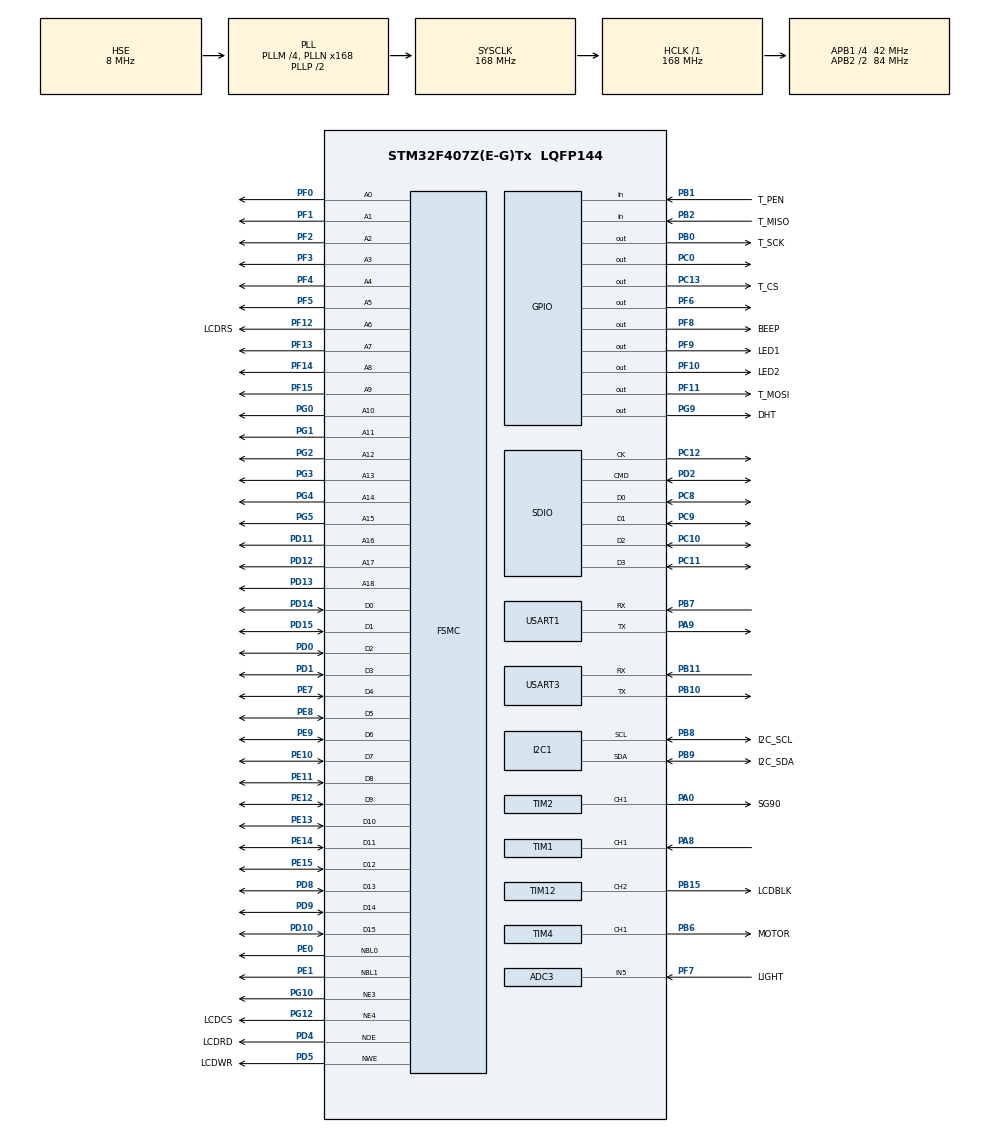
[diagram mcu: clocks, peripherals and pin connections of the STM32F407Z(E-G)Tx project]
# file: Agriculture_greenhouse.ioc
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ADC3.Channel-0\#ChannelRegularConversion=ADC_CHANNEL_5
ADC3.NbrOfConversionFlag=1
ADC3.Rank-0\#ChannelRegularConversion=1
ADC3.SamplingTime-0\#ChannelRegularConversion=ADC_SAMPLETIME_3CYCLES
Dma.Request0=SDIO_RX
Dma.Request1=SDIO_TX
Dma.SDIO_RX.0.Direction=DMA_PERIPH_TO_MEMORY
Dma.SDIO_RX.0.FIFOMode=DMA_FIFOMODE_ENABLE
Dma.SDIO_RX.0.FIFOThreshold=DMA_FIFO_THRESHOLD_FULL
Dma.SDIO_RX.0.Instance=DMA2_Stream3
Dma.SDIO_RX.0.MemBurst=DMA_MBURST_INC4
Dma.SDIO_RX.0.MemDataAlignment=DMA_MDATAALIGN_WORD
Dma.SDIO_RX.0.MemInc=DMA_MINC_ENABLE
Dma.SDIO_RX.0.Mode=DMA_PFCTRL
Dma.SDIO_RX.0.PeriphBurst=DMA_PBURST_INC4
Dma.SDIO_RX.0.PeriphDataAlignment=DMA_PDATAALIGN_WORD
Dma.SDIO_RX.0.PeriphInc=DMA_PINC_DISABLE
Dma.SDIO_RX.0.Priority=DMA_PRIORITY_HIGH
Dma.SDIO_TX.1.Direction=DMA_MEMORY_TO_PERIPH
Dma.SDIO_TX.1.FIFOMode=DMA_FIFOMODE_ENABLE
Dma.SDIO_TX.1.FIFOThreshold=DMA_FIFO_THRESHOLD_FULL
Dma.SDIO_TX.1.Instance=DMA2_Stream6
Dma.SDIO_TX.1.MemBurst=DMA_MBURST_INC4
Dma.SDIO_TX.1.MemDataAlignment=DMA_MDATAALIGN_WORD
Dma.SDIO_TX.1.MemInc=DMA_MINC_ENABLE
Dma.SDIO_TX.1.Mode=DMA_PFCTRL
Dma.SDIO_TX.1.PeriphBurst=DMA_PBURST_INC4
Dma.SDIO_TX.1.PeriphDataAlignment=DMA_PDATAALIGN_WORD
Dma.SDIO_TX.1.PeriphInc=DMA_PINC_DISABLE
Dma.SDIO_TX.1.Priority=DMA_PRIORITY_HIGH
FATFS._CODE_PAGE=936
FREERTOS.INCLUDE_vTaskDelayUntil=1
FREERTOS.MEMORY_ALLOCATION=0
FREERTOS.Tasks01=defaultTask,0,128,StartDefaultTask,Default,NULL,Dynamic,NULL,NULL
FREERTOS.configTOTAL_HEAP_SIZE=40960
FSMC.AddressSetupTime3=0
FSMC.BusTurnAroundDuration3=0
FSMC.DataSetupTime3=8
FSMC.ExtendedAddressSetupTime1=2
FSMC.ExtendedMode1=FSMC_EXTENDED_MODE_ENABLE
FSMC.WriteOperation3=FSMC_WRITE_OPERATION_ENABLE
Mcu.Family=STM32F4
Mcu.Name=STM32F407Z(E-G)Tx
Mcu.Package=LQFP144
NVIC.DMA2_Stream3_IRQn=true\:5\:0\:false\:false\:true\:true\:false\:true\:true
NVIC.DMA2_Stream6_IRQn=true\:5\:0\:false\:false\:true\:true\:false\:true\:true
NVIC.PriorityGroup=NVIC_PRIORITYGROUP_4
NVIC.SDIO_IRQn=true\:5\:0\:false\:false\:true\:true\:true\:true\:true
NVIC.TIM1_CC_IRQn=true\:5\:0\:false\:false\:true\:true\:true\:true\:true
NVIC.TIM1_UP_TIM10_IRQn=true\:5\:0\:false\:false\:true\:true\:true\:true\:true
NVIC.USART3_IRQn=true\:5\:0\:false\:false\:true\:true\:true\:true\:true
PA0-WKUP.GPIO_Label=SG90
PA0-WKUP.GPIO_PuPd=GPIO_PULLUP
PA0-WKUP.GPIO_Speed=GPIO_SPEED_FREQ_HIGH
PA0-WKUP.Signal=S_TIM2_CH1_ETR
PA13.Mode=Serial_Wire
PA13.Signal=SYS_JTMS-SWDIO
PA14.Mode=Serial_Wire
PA14.Signal=SYS_JTCK-SWCLK
PA8.GPIO_PuPd=GPIO_PULLUP
PA8.GPIO_Speed=GPIO_SPEED_FREQ_HIGH
PA8.Signal=S_TIM1_CH1
PA9.Mode=Asynchronous
PA9.Signal=USART1_TX
PB0.GPIO_Label=T_SCK
PB0.GPIO_PuPd=GPIO_PULLUP
PB0.Signal=GPIO_Output
PB1.GPIO_Label=T_PEN
PB1.GPIO_PuPd=GPIO_PULLUP
PB1.Signal=GPIO_Input
PB10.Mode=Asynchronous
PB10.Signal=USART3_TX
PB11.Mode=Asynchronous
PB11.Signal=USART3_RX
PB15.GPIO_Label=LCDBLK
PB15.GPIO_Speed=GPIO_SPEED_FREQ_HIGH
PB15.Signal=S_TIM12_CH2
PB2.GPIO_Label=T_MISO
PB2.GPIO_PuPd=GPIO_PULLUP
PB2.Signal=GPIO_Input
PB6.GPIO_Label=MOTOR
PB6.Signal=S_TIM4_CH1
PB7.Mode=Asynchronous
PB7.Signal=USART1_RX
PB8.GPIO_Label=I2C_SCL
PB8.GPIO_Pu=GPIO_PULLUP
PB8.GPIO_Speed=GPIO_SPEED_FREQ_VERY_HIGH
PB8.Mode=I2C
PB8.Signal=I2C1_SCL
PB9.GPIO_Label=I2C_SDA
PB9.GPIO_Pu=GPIO_PULLUP
PB9.Mode=I2C
PB9.Signal=I2C1_SDA
PC0.PinState=GPIO_PIN_SET
PC0.Signal=GPIO_Output
PC10.GPIO_PuPd=GPIO_PULLUP
PC10.Mode=SD_4_bits_Wide_bus
PC10.Signal=SDIO_D2
PC11.GPIO_PuPd=GPIO_PULLUP
PC11.Mode=SD_4_bits_Wide_bus
PC11.Signal=SDIO_D3
PC12.GPIO_PuPd=GPIO_PULLUP
PC12.Mode=SD_4_bits_Wide_bus
PC12.Signal=SDIO_CK
PC13-ANTI_TAMP.GPIO_Label=T_CS
PC13-ANTI_TAMP.GPIO_PuPd=GPIO_PULLUP
PC13-ANTI_TAMP.Signal=GPIO_Output
PC14-OSC32_IN.Mode=LSE-External-Oscillator
PC14-OSC32_IN.Signal=RCC_OSC32_IN
PC15-OSC32_OUT.Mode=LSE-External-Oscillator
PC15-OSC32_OUT.Signal=RCC_OSC32_OUT
PC8.GPIO_PuPd=GPIO_PULLUP
PC8.Mode=SD_4_bits_Wide_bus
PC8.Signal=SDIO_D0
PC9.GPIO_PuPd=GPIO_PULLUP
PC9.Mode=SD_4_bits_Wide_bus
PC9.Signal=SDIO_D1
PD0.GPIO_PuPd=GPIO_PULLUP
PD0.Signal=FSMC_D2_DA2
PD1.GPIO_PuPd=GPIO_PULLUP
PD1.Signal=FSMC_D3_DA3
PD10.GPIO_PuPd=GPIO_PULLUP
PD10.Signal=FSMC_D15_DA15
PD11.Signal=FSMC_A16_CLE
PD12.Signal=FSMC_A17_ALE
PD13.Signal=FSMC_A18
PD14.GPIO_PuPd=GPIO_PULLUP
PD14.Signal=FSMC_D0_DA0
PD15.GPIO_PuPd=GPIO_PULLUP
PD15.Signal=FSMC_D1_DA1
PD2.GPIO_PuPd=GPIO_PULLUP
PD2.Mode=SD_4_bits_Wide_bus
PD2.Signal=SDIO_CMD
PD4.GPIO_Label=LCDRD
PD4.GPIO_PuPd=GPIO_PULLUP
PD4.Signal=FSMC_NOE
PD5.GPIO_Label=LCDWR
PD5.GPIO_PuPd=GPIO_PULLUP
PD5.Signal=FSMC_NWE
PD8.GPIO_PuPd=GPIO_PULLUP
PD8.Signal=FSMC_D13_DA13
PD9.GPIO_PuPd=GPIO_PULLUP
PD9.Signal=FSMC_D14_DA14
PE0.Signal=FSMC_NBL0
PE1.Signal=FSMC_NBL1
PE10.GPIO_PuPd=GPIO_PULLUP
PE10.Signal=FSMC_D7_DA7
PE11.GPIO_PuPd=GPIO_PULLUP
PE11.Signal=FSMC_D8_DA8
PE12.GPIO_PuPd=GPIO_PULLUP
PE12.Signal=FSMC_D9_DA9
PE13.GPIO_PuPd=GPIO_PULLUP
PE13.Signal=FSMC_D10_DA10
PE14.GPIO_PuPd=GPIO_PULLUP
PE14.Signal=FSMC_D11_DA11
PE15.GPIO_PuPd=GPIO_PULLUP
PE15.Signal=FSMC_D12_DA12
PE7.GPIO_PuPd=GPIO_PULLUP
PE7.Signal=FSMC_D4_DA4
PE8.GPIO_PuPd=GPIO_PULLUP
PE8.Signal=FSMC_D5_DA5
PE9.GPIO_PuPd=GPIO_PULLUP
PE9.Signal=FSMC_D6_DA6
PF0.Signal=FSMC_A0
PF1.Signal=FSMC_A1
PF10.GPIO_Label=LED2
PF10.GPIO_PuPd=GPIO_NOPULL
PF10.GPIO_Speed=GPIO_SPEED_FREQ_LOW
PF10.Signal=GPIO_Output
PF11.GPIO_Label=T_MOSI
PF11.GPIO_PuPd=GPIO_PULLUP
PF11.GPIO_Speed=GPIO_SPEED_FREQ_HIGH
PF11.Signal=GPIO_Output
PF12.GPIO_Label=LCDRS
PF12.GPIO_PuPd=GPIO_PULLUP
PF12.Signal=FSMC_A6
PF13.Signal=FSMC_A7
PF14.Signal=FSMC_A8
PF15.Signal=FSMC_A9
PF2.Signal=FSMC_A2
PF3.Signal=FSMC_A3
PF4.Signal=FSMC_A4
PF5.Signal=FSMC_A5
PF6.PinState=GPIO_PIN_SET
PF6.Signal=GPIO_Output
PF7.GPIO_Label=LIGHT
PF7.Mode=IN5
PF7.Signal=ADC3_IN5
PF8.GPIO_Label=BEEP
PF8.GPIO_PuPd=GPIO_NOPULL
PF8.GPIO_Speed=GPIO_SPEED_FREQ_LOW
PF8.Signal=GPIO_Output
PF9.GPIO_Label=LED1
PF9.GPIO_PuPd=GPIO_NOPULL
PF9.GPIO_Speed=GPIO_SPEED_FREQ_LOW
PF9.Signal=GPIO_Output
PG0.Signal=FSMC_A10
PG1.Signal=FSMC_A11
PG10.Mode=NorPsramChipSelect3_3
PG10.Signal=FSMC_NE3
PG12.GPIO_Label=LCDCS
PG12.GPIO_PuPd=GPIO_PULLUP
PG12.Mode=NorPsramChipSelect4_1
PG12.Signal=FSMC_NE4
PG2.Signal=FSMC_A12
PG3.Signal=FSMC_A13
PG4.Signal=FSMC_A14
PG5.Signal=FSMC_A15
PG9.GPIO_Label=DHT
PG9.GPIO_ModeDefaultOutputPP=GPIO_MODE_OUTPUT_PP
PG9.GPIO_PuPd=GPIO_PULLUP
PG9.GPIO_Speed=GPIO_SPEED_FREQ_HIGH
PG9.PinState=GPIO_PIN_RESET
PG9.Signal=GPIO_Output
PH0-OSC_IN.Mode=HSE-External-Oscillator
PH0-OSC_IN.Signal=RCC_OSC_IN
PH1-OSC_OUT.Mode=HSE-External-Oscillator
PH1-OSC_OUT.Signal=RCC_OSC_OUT
ProjectManager.HeapSize=0x200
ProjectManager.StackSize=0x400
ProjectManager.TargetToolchain=MDK-ARM V5
RCC.48MHZClocksFreq_Value=48000000
RCC.AHBFreq_Value=168000000
RCC.APB1CLKDivider=RCC_HCLK_DIV4
RCC.APB1Freq_Value=42000000
RCC.APB1TimFreq_Value=84000000
RCC.APB2CLKDivider=RCC_HCLK_DIV2
RCC.APB2Freq_Value=84000000
RCC.APB2TimFreq_Value=168000000
RCC.CortexFreq_Value=168000000
RCC.HCLKFreq_Value=168000000
RCC.HSE_VALUE=8000000
RCC.HSI_VALUE=16000000
RCC.PLLM=4
RCC.PLLN=168
RCC.PLLQ=7
RCC.PLLSourceVirtual=RCC_PLLSOURCE_HSE
RCC.RCC_RTC_Clock_Source=RCC_RTCCLKSOURCE_LSE
RCC.RCC_RTC_Clock_SourceVirtual=RCC_RTCCLKSOURCE_LSE
RCC.SYSCLKFreq_VALUE=168000000
RCC.SYSCLKSource=RCC_SYSCLKSOURCE_PLLCLK
RCC.VCOOutputFreq_Value=336000000
SDIO.ClockDiv=4
SH.FSMC_A0.0=FSMC_A0,19b-a3
SH.FSMC_A1.0=FSMC_A1,19b-a3
SH.FSMC_A10.0=FSMC_A10,19b-a3
SH.FSMC_A11.0=FSMC_A11,19b-a3
SH.FSMC_A12.0=FSMC_A12,19b-a3
SH.FSMC_A13.0=FSMC_A13,19b-a3
SH.FSMC_A14.0=FSMC_A14,19b-a3
SH.FSMC_A15.0=FSMC_A15,19b-a3
SH.FSMC_A16_CLE.0=FSMC_A16,19b-a3
SH.FSMC_A17_ALE.0=FSMC_A17,19b-a3
SH.FSMC_A18.0=FSMC_A18,19b-a3
SH.FSMC_A2.0=FSMC_A2,19b-a3
SH.FSMC_A3.0=FSMC_A3,19b-a3
SH.FSMC_A4.0=FSMC_A4,19b-a3
SH.FSMC_A5.0=FSMC_A5,19b-a3
SH.FSMC_A6.0=FSMC_A6,A6_1
SH.FSMC_A6.1=FSMC_A6,19b-a3
SH.FSMC_A7.0=FSMC_A7,19b-a3
SH.FSMC_A8.0=FSMC_A8,19b-a3
SH.FSMC_A9.0=FSMC_A9,19b-a3
SH.FSMC_D0_DA0.0=FSMC_D0,16b-d1
SH.FSMC_D0_DA0.1=FSMC_D0,16b-d3
SH.FSMC_D10_DA10.0=FSMC_D10,16b-d1
SH.FSMC_D10_DA10.1=FSMC_D10,16b-d3
SH.FSMC_D11_DA11.0=FSMC_D11,16b-d1
SH.FSMC_D11_DA11.1=FSMC_D11,16b-d3
SH.FSMC_D12_DA12.0=FSMC_D12,16b-d1
SH.FSMC_D12_DA12.1=FSMC_D12,16b-d3
SH.FSMC_D13_DA13.0=FSMC_D13,16b-d1
SH.FSMC_D13_DA13.1=FSMC_D13,16b-d3
SH.FSMC_D14_DA14.0=FSMC_D14,16b-d1
SH.FSMC_D14_DA14.1=FSMC_D14,16b-d3
SH.FSMC_D15_DA15.0=FSMC_D15,16b-d1
SH.FSMC_D15_DA15.1=FSMC_D15,16b-d3
SH.FSMC_D1_DA1.0=FSMC_D1,16b-d1
SH.FSMC_D1_DA1.1=FSMC_D1,16b-d3
SH.FSMC_D2_DA2.0=FSMC_D2,16b-d1
SH.FSMC_D2_DA2.1=FSMC_D2,16b-d3
SH.FSMC_D3_DA3.0=FSMC_D3,16b-d1
SH.FSMC_D3_DA3.1=FSMC_D3,16b-d3
SH.FSMC_D4_DA4.0=FSMC_D4,16b-d1
SH.FSMC_D4_DA4.1=FSMC_D4,16b-d3
SH.FSMC_D5_DA5.0=FSMC_D5,16b-d1
SH.FSMC_D5_DA5.1=FSMC_D5,16b-d3
SH.FSMC_D6_DA6.0=FSMC_D6,16b-d1
SH.FSMC_D6_DA6.1=FSMC_D6,16b-d3
SH.FSMC_D7_DA7.0=FSMC_D7,16b-d1
SH.FSMC_D7_DA7.1=FSMC_D7,16b-d3
SH.FSMC_D8_DA8.0=FSMC_D8,16b-d1
SH.FSMC_D8_DA8.1=FSMC_D8,16b-d3
SH.FSMC_D9_DA9.0=FSMC_D9,16b-d1
SH.FSMC_D9_DA9.1=FSMC_D9,16b-d3
SH.FSMC_NBL0.0=FSMC_NBL0,2ByteEnable3
SH.FSMC_NBL1.0=FSMC_NBL1,2ByteEnable3
SH.FSMC_NOE.0=FSMC_NOE,Lcd1
SH.FSMC_NOE.1=FSMC_NOE,Sram3
SH.FSMC_NWE.0=FSMC_NWE,Lcd1
SH.FSMC_NWE.1=FSMC_NWE,Sram3
SH.S_TIM12_CH2.0=TIM12_CH2,PWM Generation2 CH2
SH.S_TIM1_CH1.0=TIM1_CH1,Input_Capture1_from_TI1
SH.S_TIM2_CH1_ETR.0=TIM2_CH1,PWM Generation1 CH1
SH.S_TIM4_CH1.0=TIM4_CH1,PWM Generation1 CH1
TIM1.AutoReloadPreload=TIM_AUTORELOAD_PRELOAD_ENABLE
TIM1.Channel-Input_Capture1_from_TI1=TIM_CHANNEL_1
TIM1.ICFilter_CH1=3
TIM1.Period=10000
TIM1.Prescaler=167
TIM12.Channel-PWM\ Generation2\ CH2=TIM_CHANNEL_2
TIM12.Period=255
TIM12.Prescaler=83
TIM2.Channel-PWM\ Generation1\ CH1=TIM_CHANNEL_1
TIM2.Period=1999
TIM2.Prescaler=839
TIM2.Pulse-PWM\ Generation1\ CH1=150
TIM3.Prescaler=83
TIM4.Channel-PWM\ Generation1\ CH1=TIM_CHANNEL_1
TIM4.Period=99
TIM4.Prescaler=83
USART1.VirtualMode=VM_ASYNC
USART3.VirtualMode=VM_ASYNC
VP_FATFS_VS_SDIO.Mode=SDIO
VP_FREERTOS_VS_CMSIS_V1.Mode=CMSIS_V1
VP_RTC_VS_RTC_Activate.Mode=RTC_Enabled
VP_TIM1_VS_ClockSourceINT.Mode=Internal
VP_TIM2_VS_ClockSourceINT.Mode=Internal
VP_TIM3_VS_ClockSourceINT.Mode=Internal
VP_TIM4_VS_ClockSourceINT.Mode=Internal
board=custom

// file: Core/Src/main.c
/* USER CODE BEGIN Header */
/**
  ******************************************************************************
  * @file           : main.c
  * @brief          : Main program body
  ******************************************************************************
  * @attention
  *
  * Copyright (c) 2026 STMicroelectronics.
  * All rights reserved.
  *
  * This software is licensed under terms that can be found in the LICENSE file
  * in the root directory of this software component.
  * If no LICENSE file comes with this software, it is provided AS-IS.
  *
  ******************************************************************************
  */
/* USER CODE END Header */
#include "main.h"
#include "cmsis_os.h"
#include "adc.h"
#include "dma.h"
#include "fatfs.h"
#include "i2c.h"
#include "rtc.h"
#include "sdio.h"
#include "tim.h"
#include "usart.h"
#include "gpio.h"
#include "fsmc.h"

/* USER CODE BEGIN Includes */
#include "lcd.h"
#include "lcd_draw.h"
#include "touch.h"
#include "esp8266.h"
#include "remote.h"
#include "sensor_data.h"
#include <string.h>
#include "cloud_sync.h"
#include "esp8266.h"
/* USER CODE END Includes */

/* USER CODE BEGIN PD */
#define WIFI_SSID         "hahaha"
#define WIFI_PASSWORD     "dong00407"
#define SERVER_IP         "10.17.102.190"
#define SERVER_PORT       5000
/* USER CODE END PD */

void SystemClock_Config(void);
void MX_FREERTOS_Init(void);

/* USER CODE BEGIN 0 */
// printf重定义
int fputc(int ch, FILE *f)
{
	HAL_UART_Transmit(&huart1, (uint8_t *)&ch, 1, 10);//0xffff
	return ch;
}
// int fputc(int ch, FILE *f)
// {
//     // 使用中断发送，不阻塞
//     HAL_UART_Transmit_IT(&huart1, (uint8_t *)&ch, 1);
//     // 等待发送完成（带超时）
//     uint32_t timeout = 1000;
//     while (huart1.gState != HAL_UART_STATE_READY && --timeout);
//     return ch;
// }

/*微秒延时函数*/
void delay_us(uint32_t us)
{
  __HAL_TIM_SET_COUNTER(&htim3, 0);  // 重置计数器
  HAL_TIM_Base_Start(&htim3);  // 启动定时器
  while (__HAL_TIM_GET_COUNTER(&htim3) < us);  // 等待计数完成
  HAL_TIM_Base_Stop(&htim3);  // 停止定时器
}
/* USER CODE END 0 */

int main(void)
{

  /* MCU Configuration--------------------------------------------------------*/

  /* Reset of all peripherals, Initializes the Flash interface and the Systick. */
  HAL_Init();

  /* Configure the system clock */
  SystemClock_Config();

  /* Initialize all configured peripherals */
  MX_GPIO_Init();
  MX_DMA_Init();
  MX_USART1_UART_Init();
  MX_TIM2_Init();
  MX_TIM3_Init();
  MX_TIM12_Init();
  MX_ADC3_Init();
  MX_FSMC_Init();
  MX_SDIO_SD_Init();
  MX_FATFS_Init();
  MX_RTC_Init();
  MX_USART3_UART_Init();
  MX_TIM1_Init();
  MX_I2C1_Init();
  MX_TIM4_Init();
  /* USER CODE BEGIN 2 */
  // 启动 PWM
  HAL_TIM_PWM_Start(&htim12, TIM_CHANNEL_2);
  __HAL_TIM_SetCompare(&htim12, TIM_CHANNEL_2, 125); // 设置亮度 0-255

  HAL_TIM_PWM_Start(&htim4, TIM_CHANNEL_1); // 启动定时器4的PWM输出，通道1用于控制直流电机
  HAL_TIM_PWM_Start(&htim2, TIM_CHANNEL_1); // 启动定时器2的PWM输出，通道1用于控制SG90舵机
  __HAL_TIM_SetCompare(&htim2, TIM_CHANNEL_1, 150); // 初始化舵机角度为90度

  HAL_GPIO_WritePin(LED1_GPIO_Port,LED1_Pin,GPIO_PIN_SET);
  HAL_GPIO_WritePin(LED2_GPIO_Port,LED2_Pin,GPIO_PIN_SET);

  // LCD初始化
  lcd_Init();

  // 触摸初始化
  tp_dev.init();

  // 光照传感器初始化
  BH1750_Init();

  ESP8266_SendCmd("AT+RST\r\n", "OK", 3000);
  HAL_Delay(1500);
  ESP8266_Init(WIFI_SSID, WIFI_PASSWORD);

  // 启动服务器
  ESP8266_SendCmd("AT+CIPSERVER=1,80\r\n", "OK", 2000);
  printf("服务器已启动, IP: 10.17.102.247\r\n");

  // int count = 0;
  //   while (1)
  //   {
  //       // ===== 1. 检查是否有队友指令 =====
  //   if (USART3_RX_STA & 0x8000)
  //   {
  //     char *p = strstr(USART3_RX_BUF, "+IPD,");
  //       if (p && strstr(p, "GET /control"))
  //   {
  //       printf("\r\n===== 收到指令 =====\r\n");

  //       // 1. 解析 link_id
  //       int link_id = 0;
  //       sscanf(p, "+IPD,%d,", &link_id);

  //       // 2. 构造响应体 (Body)
  //       char body[] = "{\"status\":\"ok\"}";

  //       // 3. 构造完整的 HTTP 响应头 + 响应体
  //       // 注意：这里必须包含 Content-Length，且换行符必须是 \r\n
  //       char http_response[256];
  //       int body_len = strlen(body);

  //       sprintf(http_response,
  //           "HTTP/1.1 200 OK\r\n"
  //           "Content-Type: application/json\r\n"
  //           "Content-Length: %d\r\n"
  //           "Connection: close\r\n"
  //           "\r\n"             // 空行，分隔头部和主体
  //           "%s",              // 放入 Body
  //           body_len, body
  //       );

  //       // 4. 计算准确的发送长度 (不包含字符串结尾的 \0)
  //       int total_len = strlen(http_response);

  //       // 5. 发送 AT 指令告知长度
  //       char cmd[64];
  //       sprintf(cmd, "AT+CIPSEND=%d,%d\r\n", link_id, total_len);
  //       HAL_UART_Transmit(&huart3, (uint8_t*)cmd, strlen(cmd), 1000);

  //       // 【关键修改】增加延时，等待模块准备就绪 (建议 200ms 以上)
  //       HAL_Delay(300);

  //       // 6. 发送实际的 HTTP 数据
  //       HAL_UART_Transmit(&huart3, (uint8_t*)http_response, total_len, 1000);

  //       // 7. 等待数据发送完毕，再关闭连接 (防止数据被截断)
  //       HAL_Delay(200);

  //       // 8. 关闭连接
  //       sprintf(cmd, "AT+CIPCLOSE=%d\r\n", link_id);
  //       HAL_UART_Transmit(&huart3, (uint8_t*)cmd, strlen(cmd), 1000);

  //       printf("已回复 200 OK (Len:%d)\r\n", total_len);
  //       printf("==================\r\n\r\n");
  //   }
  //       USART3_RX_STA = 0;
  //       memset(USART3_RX_BUF, 0, RX_BUFFER_SIZE);
  //   }

  //     // ===== 2. 上传数据（用ID 4）=====
  //     ESP8266_SendCmd("AT+CIPCLOSE=4\r\n", NULL, 500);
  //     HAL_Delay(200);

  //     char cmd[128];
  //     sprintf(cmd, "AT+CIPSTART=4,\"TCP\",\"%s\",%d\r\n", SERVER_IP, SERVER_PORT);
  //     if (ESP8266_SendCmd(cmd, "OK", 5000) == ESP_OK)
  //     {
  //         char json[64];
  //         sprintf(json, "{\"temp\":30.3,\"humid\":64,\"light\":18.4}");

  //         char http_req[512];
  //         sprintf(http_req,
  //             "POST /api/hardware/init HTTP/1.1\r\n"
  //             "Host: %s:%d\r\n"
  //             "Content-Type: application/json\r\n"
  //             "Content-Length: %d\r\n"
  //             "Connection: close\r\n"
  //             "\r\n"
  //             "%s",
  //             SERVER_IP, SERVER_PORT, (int)strlen(json), json);

  //         int len = strlen(http_req);
  //         sprintf(cmd, "AT+CIPSEND=4,%d\r\n", len);

  //         USART3_RX_STA = 0;
  //         memset(USART3_RX_BUF, 0, RX_BUFFER_SIZE);
  //         HAL_UART_Transmit(&huart3, (uint8_t*)cmd, strlen(cmd), 1000);

  //         uint32_t t = HAL_GetTick();
  //         while (HAL_GetTick() - t < 2000)
  //         {
  //             if (USART3_RX_STA & 0x8000 && strstr(USART3_RX_BUF, ">")) break;
  //             HAL_Delay(10);
  //         }

  //         HAL_UART_Transmit(&huart3, (uint8_t*)http_req, len, 3000);
  //         HAL_Delay(200);

  //         printf("上传%d: %s\r\n", count, json);

  //         ESP8266_SendCmd("AT+CIPCLOSE=4\r\n", NULL, 500);
  //     }

  //     count++;
  //     HAL_Delay(2000);
  //   }

//   printf("=== 测试ID4 ===\r\n");
// HAL_UART_Transmit(&huart3, (uint8_t*)"AT+CIPCLOSE=4\r\n", 14, 500);
// HAL_Delay(300);

// char cmd[128];
// sprintf(cmd, "AT+CIPSTART=4,\"TCP\",\"%s\",%d\r\n", SERVER_IP, SERVER_PORT);
// ESP_Status_t ret = ESP8266_SendCmd(cmd, "OK", 5000);
// printf("ID4结果: %d, 响应: %s\r\n", ret, USART3_RX_BUF);
// while(1);

  /* USER CODE END 2 */

  /* Call init function for freertos objects (in cmsis_os2.c) */
  MX_FREERTOS_Init();

  /* Start scheduler */
  osKernelStart();

  /* We should never get here as control is now taken by the scheduler */

  /* Infinite loop */
  while (1)
  {

  }
}

void SystemClock_Config(void)
{
  RCC_OscInitTypeDef RCC_OscInitStruct = {0};
  RCC_ClkInitTypeDef RCC_ClkInitStruct = {0};

  /** Configure the main internal regulator output voltage
  */
  __HAL_RCC_PWR_CLK_ENABLE();
  __HAL_PWR_VOLTAGESCALING_CONFIG(PWR_REGULATOR_VOLTAGE_SCALE1);

  /** Initializes the RCC Oscillators according to the specified parameters
  * in the RCC_OscInitTypeDef structure.
  */
  RCC_OscInitStruct.OscillatorType = RCC_OSCILLATORTYPE_HSE|RCC_OSCILLATORTYPE_LSE;
  RCC_OscInitStruct.HSEState = RCC_HSE_ON;
  RCC_OscInitStruct.LSEState = RCC_LSE_ON;
  RCC_OscInitStruct.PLL.PLLState = RCC_PLL_ON;
  RCC_OscInitStruct.PLL.PLLSource = RCC_PLLSOURCE_HSE;
  RCC_OscInitStruct.PLL.PLLM = 4;
  RCC_OscInitStruct.PLL.PLLN = 168;
  RCC_OscInitStruct.PLL.PLLP = RCC_PLLP_DIV2;
  RCC_OscInitStruct.PLL.PLLQ = 7;
  if (HAL_RCC_OscConfig(&RCC_OscInitStruct) != HAL_OK)
  {
    Error_Handler();
  }

  /** Initializes the CPU, AHB and APB buses clocks
  */
  RCC_ClkInitStruct.ClockType = RCC_CLOCKTYPE_HCLK|RCC_CLOCKTYPE_SYSCLK
                              |RCC_CLOCKTYPE_PCLK1|RCC_CLOCKTYPE_PCLK2;
  RCC_ClkInitStruct.SYSCLKSource = RCC_SYSCLKSOURCE_PLLCLK;
  RCC_ClkInitStruct.AHBCLKDivider = RCC_SYSCLK_DIV1;
  RCC_ClkInitStruct.APB1CLKDivider = RCC_HCLK_DIV4;
  RCC_ClkInitStruct.APB2CLKDivider = RCC_HCLK_DIV2;

  if (HAL_RCC_ClockConfig(&RCC_ClkInitStruct, FLASH_LATENCY_5) != HAL_OK)
  {
    Error_Handler();
  }
}

void Error_Handler(void)
{
  __disable_irq();
  while (1)
  {
  }
}

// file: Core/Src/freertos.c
/* USER CODE BEGIN Header */
/**
  ******************************************************************************
  * File Name          : freertos.c
  * Description        : Code for freertos applications
  ******************************************************************************
  * @attention
  *
  * Copyright (c) 2026 STMicroelectronics.
  * All rights reserved.
  *
  * This software is licensed under terms that can be found in the LICENSE file
  * in the root directory of this software component.
  * If no LICENSE file comes with this software, it is provided AS-IS.
  *
  ******************************************************************************
  */
/* USER CODE END Header */

#include "FreeRTOS.h"
#include "task.h"
#include "main.h"
#include "cmsis_os.h"

/* USER CODE BEGIN Includes */
#include "time.h"
#include "queue.h"
#include "math.h"
#include "usart.h"
#include "tim.h"
#include "timers.h"
#include "dht.h"
#include "lcd.h"
#include "lcd_draw.h"
#include "pic.h"
#include "gpio.h"
#include "adc.h"
#include "touch.h"
#include <string.h>
#include "sd.h"
#include "ss_rtc.h"
#include "SG90.h"
#include "BH1750.h"
#include "Motor.h"
#include "esp8266.h"
#include "sensor_data.h"
#include "auto_control.h"
#include "system_config.h"
/* USER CODE END Includes */

/* USER CODE BEGIN PTD */
// 触摸消息类型
typedef enum {
    TOUCH_FAN,
    TOUCH_CURTAIN,
    TOUCH_LIGHT,
    TOUCH_MODE
} TouchAction_t;

// 队列句柄
QueueHandle_t touchQueue;
/* USER CODE END PTD */

/* USER CODE BEGIN PD */
#define STORAGE_LATENCY   1800000     // 30分钟 = 1800000ms
#define MUTEX_TIMEOUT     pdMS_TO_TICKS(50)     // 互斥锁信号量获取超时50ms

float adc_history=0;     // 上次ADC采样值，用于亮度调节历史比较
static uint32_t task_watchdog[7]={0};     // 添加任务状态监控
extern const char *weekday_names[];
/* USER CODE END PD */

/* USER CODE BEGIN PM */
TaskHandle_t defaultTaskHandle = NULL;      // 默认任务（LED闪烁）
TaskHandle_t pwmDACTaskHandle = NULL;       // 自动调节屏幕亮度
TaskHandle_t screenTaskHandle = NULL;       // 屏幕显示
TaskHandle_t touchHandle = NULL;            // 触摸
TaskHandle_t SensorHandle = NULL;           // 数据采集
TaskHandle_t autocontrolHandle = NULL;      // 窗帘控制
TaskHandle_t cloudsyncHandle = NULL;        // 上传前端
TaskHandle_t espTaskHandle = NULL;
TaskHandle_t watchdogTaskHandle = NULL;     // 看门狗监控任务句柄

SemaphoreHandle_t i2c_mutex = NULL;
extern SemaphoreHandle_t MutexHandle = NULL;        // 互斥信号量（保护共享资源）
QueueHandle_t Queueretouch = NULL;                // 队列（存储触摸屏幕次数）
/* USER CODE END PM */

/* USER CODE BEGIN Variables */
void TouchTask(void *argument);             // 触摸任务（检测屏幕触摸切换页面）
void LightControlTask(void *argument);      // 自动控制光亮任务（根据环境光）
void ScreenTask(void *argument);            // 屏幕显示任务
void SensorTask(void *argument);            // 采集数据任务
void AutoControlTask(void *argument);       // 设备控制任务（风扇、舵机、led灯）
void CloudsyncTask(void *argumnet);         // 上传前端任务
void ESP8266_Task(void *argument);
void WatchdogTask(void *argument);          // 看门狗监控任务（监控各任务状态，重启系统）
/* USER CODE END Variables */
// osThreadId defaultTaskHandle;

// void StartDefaultTask(void const * argument);

void MX_FREERTOS_Init(void); /* (MISRA C 2004 rule 8.1) */

void MX_FREERTOS_Init(void)
{

  /* USER CODE BEGIN RTOS_MUTEX */
  /* add mutexes, ... */
  // 创建互斥信号量（保护共享资源）
  MutexHandle = xSemaphoreCreateMutex();
  touchQueue = xQueueCreate(5, sizeof(TouchAction_t));
  i2c_mutex = xSemaphoreCreateMutex();
  /* USER CODE END RTOS_MUTEX */

  /* USER CODE BEGIN RTOS_QUEUES */
  /* add queues, ... */
  // 创建触摸次数数据队列
  touchQueue = xQueueCreate(5, sizeof(TouchAction_t));
  // 创建ESP8266操作队列（最多缓存10个消息）
  espQueueHandle = xQueueCreate(10, sizeof(EspMessage_t));
  /* USER CODE END RTOS_QUEUES */

  /* Create the thread(s) */
  /* definition and creation of defaultTask */

  /* USER CODE BEGIN RTOS_THREADS */
  /* add threads, ... */
  SystemConfig_Init();

  // 看门狗监控（优先级1 - 保证能监控所有任务）
  BaseType_t Rewatchdog = xTaskCreate(WatchdogTask,"wtachdog",256,NULL,6,&watchdogTaskHandle);
  if(Rewatchdog == pdFALSE)
    printf("Create watchdog task failed!\r\n");

  // 触摸任务（优先级5）
  BaseType_t Retouch = xTaskCreate(TouchTask,"touch-TFT",256,(void*)NULL,3,&touchHandle);
  if(Retouch == pdFALSE)
    printf("Create touch-TFT task falied! \r\n");

  // 屏幕显示（优先级4）
  BaseType_t Rescreen = xTaskCreate(ScreenTask,"screen",2048,NULL,4,&screenTaskHandle);
  if(Rescreen == pdFALSE)
    printf("Create screen task falied!\r\n");

  // 传感器采集（优先级3）
  BaseType_t Resensor = xTaskCreate(SensorTask,"Sensor",256,NULL,3,&SensorHandle);
  if(Resensor == pdFALSE)
    printf("Create Sensor task failed!\r\n");

  // 自动亮度控制（优先级3）
  BaseType_t RepwmDAC = xTaskCreate(LightControlTask,"PWM-DAC",256,NULL,3,&pwmDACTaskHandle);
  if(RepwmDAC == pdFALSE)
    printf("Create pwm task failed!\r\n");

  // 设备控制（优先级2）
  BaseType_t Reauto = xTaskCreate(AutoControlTask,"Auto",256,NULL,2,&autocontrolHandle);
  if(Reauto == pdFALSE)
    printf("Create Autocontrol task failed!\r\n");

  // 创建控制服务器任务
  BaseType_t Resesp = xTaskCreate(ESP8266_Task, "esp8266", 512, NULL, 3, &espTaskHandle);
  if(Resesp == pdFALSE)
    printf("Create ESP8266 task failed!\r\n");

  // 云端上传（优先级1）
  BaseType_t Recloud = xTaskCreate(CloudsyncTask,"cloud",1024,NULL,1,&cloudsyncHandle);
  if(Recloud == pdFALSE)
    printf("Creat Cloud task faied!\r\n");
  lcd_showpicture(0, 0, 320, 480, gImage_back);

  // lcd_show_string(10,10,24,"2026-7-5",DARKBLUE);
  // lcd_show_string(140,10,24,"14:10",0x0140);
  // lcd_showchinese(25,70,24,"温度", 0x0180);
  // lcd_show_string(30,110,32,"26.5",DARKBLUE);
  // lcd_show_string(100,200,32,"890",MID_GREEN);
  // lcd_show_string(100,200,32,"890",DARK_GREEN);
  // lcd_show_string(100,200,32,"890",DIM_GREEN);
  /* USER CODE END RTOS_THREADS */

}

/* USER CODE END StartDefaultTask */

/* USER CODE BEGIN Application */
/**
 * @brief 触摸任务 - 检测屏幕触摸切换页面
 * @param argument 任务参数
 */
void TouchTask(void *argument)
{
  uint32_t last_scan = 0;
  uint32_t touch_start_time = 0;
  uint32_t last_action_time = 0;
  uint8_t touch_state = 0;
  uint8_t last_touch_state = 0;
  uint16_t x = 0, y = 0;
  uint32_t scan_timeout = 0;        // 扫描超时

  for(;;)
  {
    vTaskDelayUntil(&last_scan, pdMS_TO_TICKS(50));
    task_watchdog[0]++;

    // 记录扫描开始时间
    scan_timeout = xTaskGetTickCount();
    tp_dev.scan(0);

    // 如果扫描耗时超过40ms，说明卡在SPI里了，跳过本次
    if ((xTaskGetTickCount() - scan_timeout) > pdMS_TO_TICKS(40))
    {
        // 扫描卡住了，强制释放并跳过
        tp_dev.sta &= ~TP_PRES_DOWN;
        printf("[Touch] scan timeout, skip\r\n");
        continue;
    }
    uint8_t current_touch = (tp_dev.sta & TP_PRES_DOWN) ? 1 : 0;

    if (current_touch && !last_touch_state)
    {
      x = tp_dev.x[0];
      y = tp_dev.y[0];
      touch_start_time = xTaskGetTickCount();
      touch_state = 1;
    }

    if (touch_state == 1 && current_touch)
    {
      uint32_t now = xTaskGetTickCount();
      if ((now - last_action_time) > pdMS_TO_TICKS(300))
      {
        TouchAction_t action;
        uint8_t send = 0;

        if (x > 20 && x < 98 && y > 390 && y < 420) {
          if (g_sys_config.system_mode == 0) {
            action = TOUCH_FAN;
            send = 1;
          }
        }
        else if (x > 125 && x < 200 && y > 390 && y < 420) {
          if (g_sys_config.system_mode == 0) {
            action = TOUCH_CURTAIN;
            send = 1;
          }
        }
        else if (x > 220 && x < 290 && y > 390 && y < 420) {
          if (g_sys_config.system_mode == 0) {
            action = TOUCH_LIGHT;
            send = 1;
          }
        }
        else if (x > 250 && x < 300 && y > 10 && y < 38) {
          action = TOUCH_MODE;
          send = 1;
        }

        if (send) {
          xQueueSend(touchQueue, &action, 0);  // 只发消息！
          last_action_time = now;
          touch_state = 2;
        }
      }
    }

    if (!current_touch && last_touch_state)
    {
      touch_state = 0;
    }

    if (touch_state >= 1 && (xTaskGetTickCount() - touch_start_time) > pdMS_TO_TICKS(1000))
    {
      touch_state = 0;
      current_touch = 0;
      tp_dev.sta &= ~TP_PRES_DOWN;
    }
    last_touch_state = current_touch;
  }
}

/**
 * @brief 自动亮度控制任务 - 根据环境光传感器调节屏幕亮度
 * @param argument 任务参数
 */
void LightControlTask(void *argument)
{
  uint32_t adc3x;        // ADC采样值（0-4095）
  uint8_t pwmdac_val;    // PWM比较值（0-255）
  float light_val;       // 光照电压值

  for(;;)
  {
    vTaskDelay(pdMS_TO_TICKS(100));  // 降低采样频率到100ms

    // 更新看门狗计数
    task_watchdog[1]++;

    // 读取ADC，添加超时保护
    adc3x = ADC3_result(20);
    light_val = (float)adc3x * (3.3f / 4096.0f);

    // 如果光照变化超过阈值，调整亮度
    if(fabsf(light_val - adc_history) >= 0.5f)
    {
      pwmdac_val = (uint8_t)(light_val * (256.0f / 3.3f));
      if(pwmdac_val > 255) pwmdac_val = 255;
      pwmdac_val = 255 - pwmdac_val;  // 反转

      // 使用互斥信号量保护PWM设置
      if(xSemaphoreTake(MutexHandle, MUTEX_TIMEOUT) == pdTRUE)
      {
        __HAL_TIM_SetCompare(&htim12, TIM_CHANNEL_2, pwmdac_val);
        adc_history = light_val;
        xSemaphoreGive(MutexHandle);
      }
    }
  }
}

/**
 * @brief 设备控制任务
 * @param argument 无
 * @note 全自动模式下执行自动控制，每5秒循环一次
 */
void AutoControlTask(void *argument)
{
  SS_RTC_Time_t time;
  static uint8_t first_run = 1;

  if (DataLogger_Init() != 1) {
    printf("[CLOUD] SD卡挂载失败\r\n");
  } else {
    printf("[CLOUD] SD卡挂载成功\n");
  }
  // 启动30分钟自动保存定时器
  SystemConfig_StartAutoSaveTimer();

  // 上电延时10秒再启动自动控制
  vTaskDelay(pdMS_TO_TICKS(30000));

  while (1)
  {
    task_watchdog[2]++;

    if (first_run) {
      Fan_SetLevel(g_sys_config.fan_level);
      if (g_sys_config.curtain_state) Curtain_On();
      else Curtain_Off();
      printf("[AUTO] 设备状态已恢复\r\n");
      first_run = 0;
    }

    SS_RTC_GetTime(&time);
    if (time.hours == 20 && time.minutes == 0 && time.seconds == 0) {
      System_AutoRecovery();
    }

    if (g_sys_config.system_mode == 1) {
      // 全自动模式
      AutoControl_All(&g_sys_config);
    } else {
      // 手动模式：风扇自动匹配
      FanAutoLevel_Manual(&g_sys_config);
    }

    SystemConfig_CheckSave();   // 检查是否需要保存

    vTaskDelay(pdMS_TO_TICKS(5000));
  }
}

/*
 * @brief 数据采集任务
 * @param argument 无
 * @note 1s采集一次
 */
void SensorTask(void *argument)
{
  TickType_t xLastWakeTime = xTaskGetTickCount();

  printf("[Sensor] 采集任务启动, 1s采集一次\r\n");

  while (1)
  {
    // 更新看门狗计数
    task_watchdog[3]++;

    // 采集传感器
    Sensor_Update();         // 读取传感器
    printf("[Sensor] T:%.1f H:%d L:%.1f\r\n",
           g_sensor_data.temperature,
           g_sensor_data.humidity,
           g_sensor_data.light);

    // 每1秒采集一次
    vTaskDelayUntil(&xLastWakeTime, pdMS_TO_TICKS(1000));
  }
}

/*
 * @brief 上传前端任务
 * @param argument 无
 * @note 每10s上传一次数据
 */
void CloudsyncTask(void *argument)
{
  vTaskDelay(pdMS_TO_TICKS(3000));
  printf("[CLOUD] 2s上报一次\r\n");

  TickType_t xLastWakeTime = xTaskGetTickCount();

  while (1)
  {
    task_watchdog[4]++;

    // 存储数据到SD卡
    DataLogger_StoreCurrent();

    EspMessage_t msg;
    msg.type = MSG_UPLOAD_DATA;
    xQueueSend(espQueueHandle, &msg, 0);

    vTaskDelayUntil(&xLastWakeTime, pdMS_TO_TICKS(2000));
  }
}

/**
 * @brief ESP8266处理任务
 */
void ESP8266_Task(void *argument)
{
  EspMessage_t msg;
  dma_tx_done = xSemaphoreCreateBinary();
  espQueueHandle = xQueueCreate(4, sizeof(EspMessage_t));

  TickType_t xLastUpload = 0;
  uint8_t uploading = 0;
  uint8_t pending_status = 0;

  while(1)
  {
    task_watchdog[6]++;
    ESP8266_ProcessRequest();

    if (xQueueReceive(espQueueHandle, &msg, 0) == pdTRUE)
    {
        if (msg.type == MSG_UPLOAD_STATUS) pending_status = 1;

        EspMessage_t dummy;
        while (xQueueReceive(espQueueHandle, &dummy, 0) == pdTRUE)
        {
            if (dummy.type == MSG_UPLOAD_STATUS) pending_status = 1;
        }
    }

    if (pending_status || xTaskGetTickCount() - xLastUpload >= pdMS_TO_TICKS(2000))
    {
        upload_sensor_data(pending_status ? 1 : 0);
        pending_status = 0;
        xLastUpload = xTaskGetTickCount();
    }

    vTaskDelay(pdMS_TO_TICKS(20));
  }
}

/**
 * @brief 屏幕显示任务
 * @param argument 任务参数
 */
void ScreenTask(void *argument)
{
  SS_RTC_Time_t rtc_time;
  uint8_t fan_laststate=2;
  uint8_t curtain_laststate=2;
  uint8_t light_laststate=2;
  uint8_t mode_last=2;
  uint8_t fan_lastlevel=6;
  uint16_t temp_history=0;    // 上次温度采样值，用于温度调节历史比较
  uint16_t humi_history=0;    // 上次湿度采样值，用于湿度调节历史比较
  uint16_t light_history=0;   // 上次光照采样值，用于光照调节历史比较
  char humi_str[8];    // 湿度字符串
  char light_str[16];  // 光照字符串
  char temp_str[16];   // 温度字符串

  // 显示
  lcd_showchinese(105, 116, 24, "℃", DARKBLUE,WHITE);
  lcd_show_string(250,116,24,"%RH",DARKBLUE,WHITE);
  lcd_show_string(182,210,24,"lux",DARKBLUE,WHITE);
  lcd_showchinese(35,78,24,"温度",BLACK,WHITE);
  lcd_showchinese(185, 78, 24, "湿度", BLACK,WHITE);
  lcd_showchinese(120,168,24,"光照",BLACK,WHITE);
  lcd_showchinese(40,330,24,"风扇",0x0140,WHITE);
  lcd_showchinese(135,330,24,"卷帘",0x0140,WHITE);
  lcd_showchinese(222,330,24,"补光灯",0x0140,WHITE);
  lcd_showchinese(63,363,16,"档",0x2104,WHITE);
  lcd_show_circle(32,371,8,0x4208);  // 画圈
  LCD_DrawLine(28,371,38,371,0X4208);
  lcd_show_circle(90,371,8,0x4208);  // 画圈
  LCD_DrawLine(86,371,96,371,0X4208);
  LCD_DrawLine(90,366,90,377,0X4208);

  for(;;)
  {
    vTaskDelay(pdMS_TO_TICKS(200));

    // 更新看门狗计数
    task_watchdog[5]++;

    SS_RTC_GetTime(&rtc_time);  // 获取当前时间

    // 显示时间和日期
    char time_str[16],time_str1[16],data_str[16];
    sprintf(data_str, "%02d-%d-%d", rtc_time.year, rtc_time.month, rtc_time.day);
    sprintf(time_str1, "%02d:%02d", rtc_time.hours, rtc_time.minutes);
    sprintf(time_str, "%02d:%02d:%02d", rtc_time.hours, rtc_time.minutes, rtc_time.seconds);
    sprintf(temp_str, "%.1f", g_sensor_data.temperature);
    sprintf(humi_str, "%.1f",(float) g_sensor_data.humidity);
    sprintf(light_str,"%.1f",g_sensor_data.light);

    // 加互斥锁保护LCD操作
    if(xSemaphoreTake(MutexHandle, pdMS_TO_TICKS(50)) == pdTRUE)
    {
      lcd_show_string(10,10,24,data_str,0x0140,WHITE);
      update_time(135, 10, 24, time_str1);
      update_time_display(120,450,24,time_str);
      if(temp_history!=g_sensor_data.temperature){
        lcd_show_string(30, 110, 32, temp_str, DARKBLUE,WHITE);
        temp_history=g_sensor_data.temperature;
      }
      if(humi_history!=g_sensor_data.humidity){
        lcd_show_string(180, 110, 32, humi_str, DARKBLUE,WHITE);
        humi_history=g_sensor_data.humidity;
      }
      if(light_history!=g_sensor_data.light){
        lcd_show_string(110, 205, 32, light_str, DARKBLUE,WHITE);
        light_history=g_sensor_data.light;
      }
      xSemaphoreGive(MutexHandle);
    }

    if(fan_lastlevel!=g_sys_config.fan_level)
    {
      lcd_shownum(48,363,16,g_sys_config.fan_level,0x2104);
      fan_lastlevel=g_sys_config.fan_level;
    }

    if((fan_laststate!= g_sys_config.fan_state) || (curtain_laststate!= g_sys_config.curtain_state) || (light_laststate !=g_sys_config.light_state) ||(mode_last!=g_sys_config.system_mode))
    {
      if(fan_laststate!=g_sys_config.fan_state)
      {
        lcd_shownum(26,270,16,g_sys_config.fan_state,0x02104);
        if(g_sys_config.fan_state)
        {
          lcd_showchinese(40,393,24,"关闭",BRRED,RED);
        }
        else{
          lcd_showchinese(40,393,24,"打开",0x0180,GREEN);
        }
        fan_laststate=g_sys_config.fan_state;
      }
      if(curtain_laststate!= g_sys_config.curtain_state)
      {
        lcd_shownum(126,270,16,g_sys_config.curtain_state,0x0140);
        if(g_sys_config.curtain_state)
        {
          lcd_showchinese(137,393,24,"关闭",BRRED,RED);
          lcd_showchinese(135,363,16,"运行中",0x2104,WHITE);
        }
        else{
          lcd_showchinese(137,393,24,"打开",0x0180,GREEN);
          lcd_showchinese(135,363,16,"已关闭",0x2104,WHITE);
        }
        curtain_laststate=g_sys_config.curtain_state;
      }
      if(light_laststate != g_sys_config.light_state)
      {
        lcd_shownum(222,270,16,g_sys_config.curtain_state,0x0140);
        if(g_sys_config.light_state)
        {
          lcd_showchinese(230,393,24,"关闭",BRRED,RED);
          lcd_showchinese(230,363,16,"运行中",0x2104,WHITE);
        }
        else{
          lcd_showchinese(230,393,24,"打开",0x0180,GREEN);
          lcd_showchinese(230,363,16,"已关闭",0x2104,WHITE);
        }
        light_laststate = g_sys_config.light_state;
      }
      if(mode_last!=g_sys_config.system_mode)
      {
        if(g_sys_config.system_mode)
        {;
          lcd_showchinese(250,10,24,"自动",0x0180,GREEN);
          mode_last=g_sys_config.system_mode;
        }
        else{
          lcd_showchinese(250,10,24,"手动",BRRED,RED);
          mode_last=g_sys_config.system_mode;
        }
      }
    }
    // 处理触摸消息（在LCD操作之后）
    TouchAction_t action;
    if (xQueueReceive(touchQueue, &action, 0) == pdTRUE) {
      switch(action) {
        case TOUCH_FAN:
            if (g_sys_config.fan_state == 0)
                Remote_SetFan(1);
            else
                Remote_SetFan(0);
            break;
        case TOUCH_CURTAIN:
            Manual_SetCurtain(!g_sys_config.curtain_state);
            break;
        case TOUCH_LIGHT:
            Manual_SetLight(!g_sys_config.light_state);
            break;
        case TOUCH_MODE:
            if (g_sys_config.system_mode == 1)
              Manual_SetSystemManual();
            else
              Manual_SetSystemAuto();
            break;
      }
      // 通知ESP8266状态变化
      EspMessage_t msg;
      msg.type = MSG_UPLOAD_STATUS;
      xQueueSend(espQueueHandle, &msg, 0);
    }
  }
}

/**
 * @brief 看门狗监控任务 - 监控各任务是否卡死
 * @param argument 任务参数
 */
void WatchdogTask(void *argument)
{
  uint32_t last_values[7] = {0};
  uint32_t stuck_count[7] = {0};

  // 初始化所有last_values为当前值，避免初始误判
  vTaskDelay(pdMS_TO_TICKS(20000));
  for(int i = 0; i < 7; i++) {
    last_values[i] = task_watchdog[i];  // 初始化基准值
  }

  for(;;)
  {
    vTaskDelay(pdMS_TO_TICKS(5000));

    int total_stuck = 0;

    for(int i = 0; i < 7; i++)
    {
      if(task_watchdog[i] == last_values[i])
      {
        stuck_count[i]++;
        if(stuck_count[i] >= 6) {  // 放宽到30秒
          total_stuck++;
          printf("[Watchdog] Task %d stuck! (%d/6)\n", i, stuck_count[i]);
        }
      }
      else
      {
        stuck_count[i] = 0;  // 只要更新一次就清零
      }
      last_values[i] = task_watchdog[i];
    }

    if(total_stuck >= 2) {
      printf("[Watchdog] Multiple tasks stuck! System reset!\n");
      HAL_Delay(100);
      NVIC_SystemReset();
    }
  }
}
/* USER CODE END Application */
